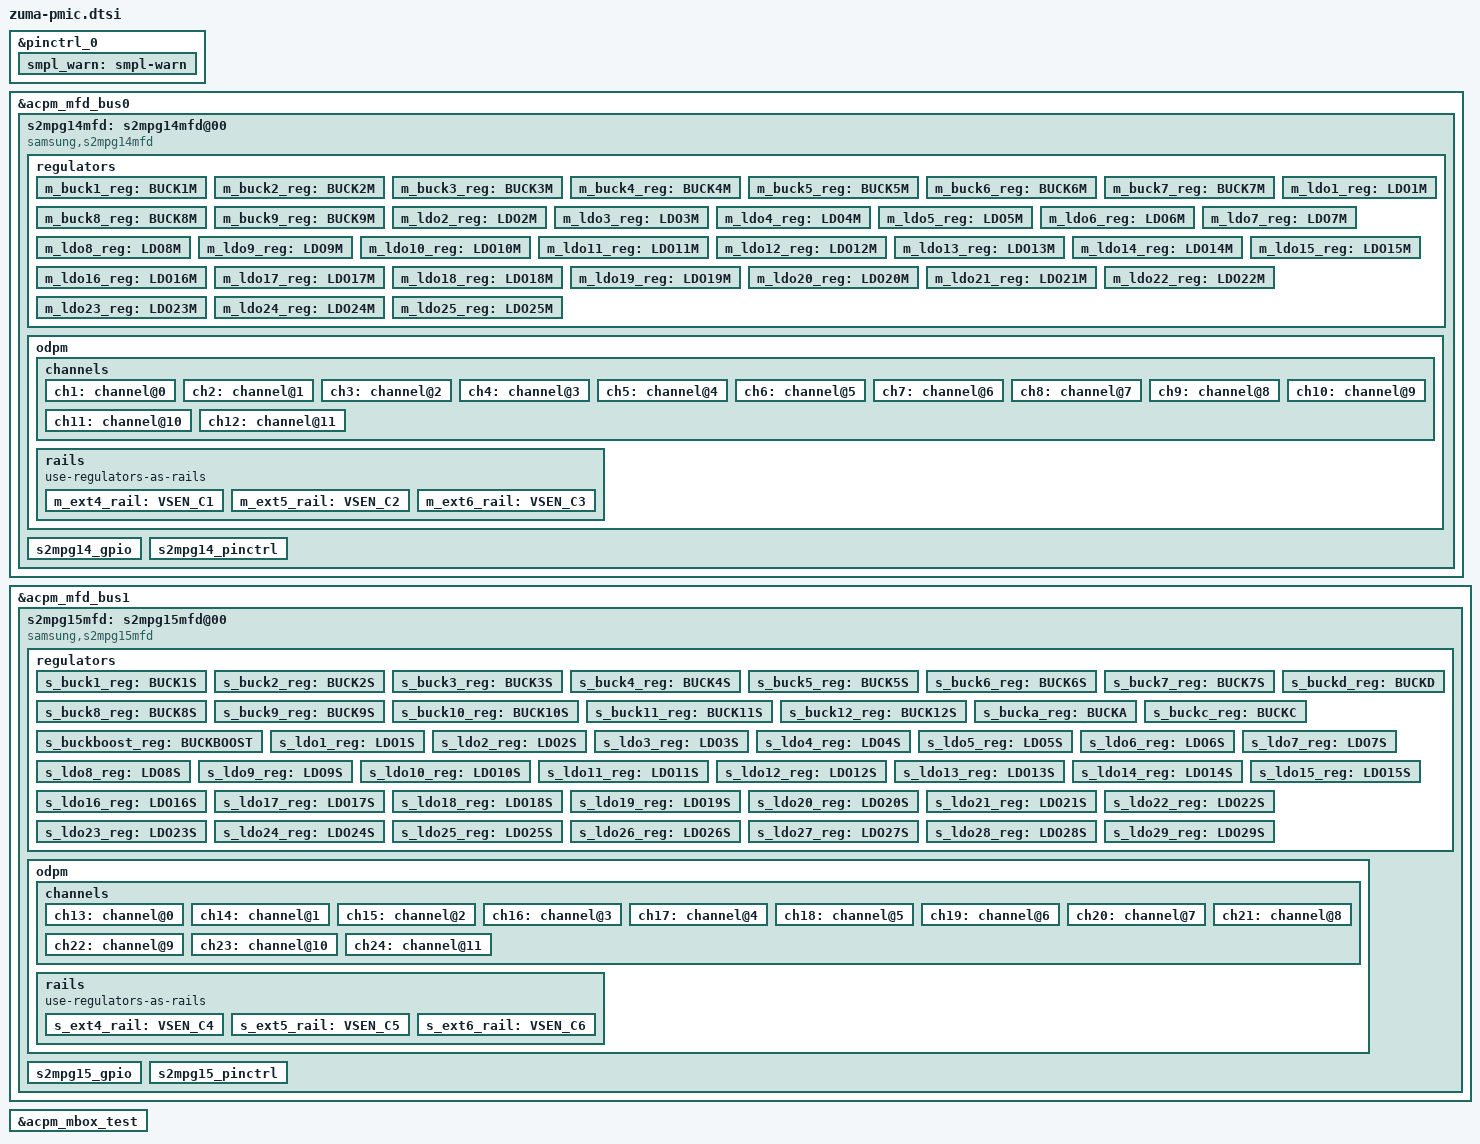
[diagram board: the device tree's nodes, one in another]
// SPDX-License-Identifier: GPL-2.0-only
/*
 * zuma pmic device tree source
 *
 * Copyright 2022 Google LLC.
 *
 */

#include <dt-bindings/gpio/gpio.h>
#include <dt-bindings/power/google-power.h>
#include <dt-bindings/power/s2mpg1x-power.h>
#include <dt-bindings/regulator/samsung,s2mpg-regulator.h>
#include <dt-bindings/interrupt-controller/zuma.h>

&pinctrl_0 {
	smpl_warn: smpl-warn {
		samsung,pins = "gpa9-4";
		samsung,pin-function = <EXYNOS_PIN_FUNC_EINT>;
		samsung,pin-pud = <EXYNOS_PIN_PULL_NONE>;
		samsung,pin-drv = <ZUMA_PIN_DRV_X1>;
	};
};

&acpm_mfd_bus0 {
	#address-cells = <1>;
	#size-cells = <0>;
	status = "okay";
	s2mpg14mfd: s2mpg14mfd@00 {
		compatible = "samsung,s2mpg14mfd";
		dev-name = "s2mpg14mfd";
		acpm-ipc-channel = <2>;
		acpm-speedy-channel = <0>;
		s2mpg14,wakeup = "enabled";
		reg = <0x1f>;
		interrupts = <GIC_SPI IRQ_INTCOMB_VGPIO2AP_ALIVE IRQ_TYPE_LEVEL_HIGH>;
		interrupt-parent = <&gic>;
		pinctrl-names = "default";
		pinctrl-0 = <&smpl_warn>;
		gpios = <&gpa9 4 GPIO_ACTIVE_LOW>,		/* SMPL_WARN_R_L */
			<&gpa10 0 GPIO_ACTIVE_HIGH>,		/* OCP_WARN_CPUCL1_R */
			<&gpa10 1 GPIO_ACTIVE_HIGH>,		/* OCP_WARN_CPUCL2_R */
			<&gpa10 2 GPIO_ACTIVE_HIGH>,		/* SOFT_OCP_WARN_CPUCL1_R */
			<&gpa10 3 GPIO_ACTIVE_HIGH>,		/* SOFT_OCP_WARN_CPUCL2_R */
			<&gpa9 2 GPIO_ACTIVE_HIGH>,		/* OCP_WARN_TPU_R */
			<&gpa9 3 GPIO_ACTIVE_HIGH>;		/* SOFT_OCP_WARN_TPU_R */
		#thermal-sensor-cells = <1>;

		/* SMPL_WARN */
		smpl_warn_en = <1>; /* 1 : enable , 0 : disable */
		smpl_warn_vth = <SMPL_2_9V>;
		/* SMPL_Hys[4:3] 00(Reserved), 01(200mV) */
		/*		 10(300mV), 11(Reserved) */
		smpl_warn_hys = <SMPL_HYST_200MV>;

		b2_ocp_warn_en = <OCP_WARN_ENABLE>;
		b2_ocp_warn_cnt = <OCP_WARN_2_CLOCK>;
		b2_ocp_warn_dvs_mask = <OCP_WARN_NOT_MASKED>;
		b2_ocp_warn_lvl = <OCP_WARN_LVL_2PH_8_A>;
		b2_ocp_warn_debounce_clk = <3>;

		b3_ocp_warn_en = <OCP_WARN_ENABLE>;
		b3_ocp_warn_cnt = <OCP_WARN_2_CLOCK>;
		b3_ocp_warn_dvs_mask = <OCP_WARN_NOT_MASKED>;
		b3_ocp_warn_lvl = <OCP_WARN_LVL_3PH_13_50_A>;
		b3_ocp_warn_debounce_clk = <3>;

		b7_ocp_warn_en = <OCP_WARN_ENABLE>;
		b7_ocp_warn_cnt = <OCP_WARN_2_CLOCK>;
		b7_ocp_warn_dvs_mask = <OCP_WARN_NOT_MASKED>;
		b7_ocp_warn_lvl = <OCP_WARN_LVL_3PH_13_50_A>;
		b7_ocp_warn_debounce_clk = <3>;

		b2_soft_ocp_warn_en = <OCP_WARN_ENABLE>;
		b2_soft_ocp_warn_cnt = <OCP_WARN_2_CLOCK>;
		b2_soft_ocp_warn_dvs_mask = <OCP_WARN_NOT_MASKED>;
		b2_soft_ocp_warn_lvl = <OCP_WARN_LVL_2PH_8_A>;
		b2_soft_ocp_warn_debounce_clk = <3>;

		b3_soft_ocp_warn_en = <OCP_WARN_ENABLE>;
		b3_soft_ocp_warn_cnt = <OCP_WARN_2_CLOCK>;
		b3_soft_ocp_warn_dvs_mask = <OCP_WARN_NOT_MASKED>;
		b3_soft_ocp_warn_lvl = <OCP_WARN_LVL_3PH_13_50_A>;
		b3_soft_ocp_warn_debounce_clk = <3>;

		b7_soft_ocp_warn_en = <OCP_WARN_ENABLE>;
		b7_soft_ocp_warn_cnt = <OCP_WARN_2_CLOCK>;
		b7_soft_ocp_warn_dvs_mask = <OCP_WARN_NOT_MASKED>;
		b7_soft_ocp_warn_lvl = <OCP_WARN_LVL_3PH_13_50_A>;
		b7_soft_ocp_warn_debounce_clk = <3>;

		/* BUCK OCP Detection */
		buck_ocp_ctrl1 = <0xBB>;
		buck_ocp_ctrl2 = <0xBB>;
		buck_ocp_ctrl3 = <0xBB>;
		buck_ocp_ctrl4 = <0xBB>;
		buck_ocp_ctrl5 = <0xBB>;

		/* RTC: wtsr/smpl */
		wtsr_en = <1>;
		coldrst_en = "disabled";
		smpl_en = "enabled";
		wtsr_timer_val = <RTC_WTSRT_2_000_SEC>;
		coldrst_timer_val = <RTC_WTSR_COLDTIMER_256_MSEC>;
		smpl_timer_val = <RTC_SMPLT_1_93_SEC>;
		sub_smpl_en = "disabled";
		check_jigon = <0>;

		/* RTC: If first boot, reset rtc to 1/1/2022 12:00:00(Sat) */
		init_time,sec = <0>;
		init_time,min = <0>;
		init_time,hour = <12>;
		init_time,mday = <1>;
		init_time,mon = <0>;
		init_time,year = <122>;
		init_time,wday = <6>;

		/* PCTRLSEL(VGPIO) 1~11 (CONTROL_SEL#) */
		sel_vgpio = <0xD3 0x1C 0xE3 0x01 0x63 0xC6
			0xE1 0x47 0x4D 0x96 0x09>;

		regulators {
			m_buck1_reg: BUCK1M {
				regulator-name = "S2MPG14_BUCK1";
				regulator-min-microvolt = <450000>;
				regulator-max-microvolt = <1300000>;
				regulator-always-on;
				regulator-initial-mode = <SEC_OPMODE_ON>;
				channel-mux-selection = <0x01>;
				schematic-name = "S1M_VDD_MIF";
				subsys-name = "MIF";
				buck_rail;
				channel-en-byte-offset = <0>;
				channel-en-index = <0x01>;
			};

			m_buck2_reg: BUCK2M {
				regulator-name = "S2MPG14_BUCK2";
				regulator-min-microvolt = <450000>;
				regulator-max-microvolt = <1300000>;
				regulator-always-on;
				regulator-initial-mode = <SEC_OPMODE_SUSPEND>;
				channel-mux-selection = <0x02>;
				schematic-name = "S2M_VDD_CPUCL2";
				subsys-name = "CPU(BIG)";
				buck_rail;
				channel-en-byte-offset = <0>;
				channel-en-index = <0x02>;
				odpm_disable_in_sleep;
			};

			m_buck3_reg: BUCK3M {
				regulator-name = "S2MPG14_BUCK3";
				regulator-min-microvolt = <450000>;
				regulator-max-microvolt = <1300000>;
				regulator-always-on;
				regulator-initial-mode = <SEC_OPMODE_SUSPEND>;
				channel-mux-selection = <0x03>;
				schematic-name = "S3M_VDD_CPUCL1";
				subsys-name = "CPU(MID)";
				buck_rail;
				channel-en-byte-offset = <0>;
				channel-en-index = <0x04>;
				odpm_disable_in_sleep;
			};

			m_buck4_reg: BUCK4M {
				regulator-name = "S2MPG14_BUCK4";
				regulator-min-microvolt = <450000>;
				regulator-max-microvolt = <1300000>;
				regulator-always-on;
				regulator-initial-mode = <SEC_OPMODE_SUSPEND>;
				channel-mux-selection = <0x04>;
				schematic-name = "S4M_VDD_CPUCL0";
				subsys-name = "CPU(LITTLE)";
				buck_rail;
				channel-en-byte-offset = <0>;
				channel-en-index = <0x08>;
				odpm_disable_in_sleep;
			};

			m_buck5_reg: BUCK5M {
				regulator-name = "S2MPG14_BUCK5";
				regulator-min-microvolt = <450000>;
				regulator-max-microvolt = <1300000>;
				regulator-always-on;
				regulator-initial-mode = <SEC_OPMODE_ON>;
				channel-mux-selection = <0x05>;
				schematic-name = "S5M_VDD_INT";
				subsys-name = "INT";
				buck_rail;
				channel-en-byte-offset = <0>;
				channel-en-index = <0x10>;
			};

			m_buck6_reg: BUCK6M {
				regulator-name = "S2MPG14_BUCK6";
				regulator-min-microvolt = <450000>;
				regulator-max-microvolt = <1500000>;
				regulator-always-on;
				regulator-initial-mode = <SEC_OPMODE_ON>;
				channel-mux-selection = <0x06>;
				schematic-name = "S6M_LLDO1";
				subsys-name = "LDO";
				buck_rail;
				channel-en-byte-offset = <0>;
				channel-en-index = <0x20>;
				odpm_disable_in_sleep;
			};

			m_buck7_reg: BUCK7M {
				regulator-name = "S2MPG14_BUCK7";
				regulator-min-microvolt = <450000>;
				regulator-max-microvolt = <1300000>;
				regulator-always-on;
				regulator-initial-mode = <SEC_OPMODE_SUSPEND>;
				channel-mux-selection = <0x07>;
				schematic-name = "S7M_VDD_TPU";
				subsys-name = "TPU";
				buck_rail;
				channel-en-byte-offset = <0>;
				channel-en-index = <0x40>;
				odpm_disable_in_sleep;
			};

			m_buck8_reg: BUCK8M {
				regulator-name = "S2MPG14_BUCK8";
				regulator-min-microvolt = <450000>;
				regulator-max-microvolt = <1300000>;
				regulator-always-on;
				regulator-initial-mode = <SEC_OPMODE_ON>;
				channel-mux-selection = <0x08>;
				schematic-name = "S8M_LLDO2";
				subsys-name = "LDO";
				buck_rail;
				channel-en-byte-offset = <0>;
				channel-en-index = <0x80>;
			};

			m_buck9_reg: BUCK9M {
				regulator-name = "S2MPG14_BUCK9";
				regulator-min-microvolt = <450000>;
				regulator-max-microvolt = <1300000>;
				regulator-always-on;
				regulator-initial-mode = <SEC_OPMODE_SUSPEND>;
				channel-mux-selection = <0x09>;
				schematic-name = "S9M_VDD_CPUCL0_M";
				subsys-name = "CPU(LITTLE)";
				buck_rail;
				channel-en-byte-offset = <1>;
				channel-en-index = <0x01>;
				odpm_disable_in_sleep;
			};

			m_ldo1_reg: LDO1M {
				regulator-name = "S2MPG14_LDO1";
				regulator-min-microvolt = <450000>;
				regulator-max-microvolt = <950000>;
				regulator-always-on;
				regulator-initial-mode = <SEC_OPMODE_ON>;
				channel-mux-selection = <0x21>;
				schematic-name = "L1M_ALIVE";
				subsys-name = "ALIVE";
			};

			m_ldo2_reg: LDO2M {
				regulator-name = "S2MPG14_LDO2";
				regulator-min-microvolt = <1600000>;
				regulator-max-microvolt = <1950000>;
				regulator-always-on;
				regulator-initial-mode = <SEC_OPMODE_ON>;
				channel-mux-selection = <0x22>;
				schematic-name = "L2M_ALIVE";
				subsys-name = "ALIVE";
			};

			m_ldo3_reg: LDO3M {
				regulator-name = "S2MPG14_LDO3";
				regulator-min-microvolt = <450000>;
				regulator-max-microvolt = <950000>;
				regulator-always-on;
				regulator-initial-mode = <SEC_OPMODE_ON>;
				channel-mux-selection = <0x23>;
				schematic-name = "L3M_VDD_AOC_RET";
				subsys-name = "AOC";
			};

			m_ldo4_reg: LDO4M {
				regulator-name = "S2MPG14_LDO4";
				regulator-min-microvolt = <2500000>;
				regulator-max-microvolt = <3300000>;
				regulator-always-on;
				regulator-initial-mode = <SEC_OPMODE_ON>;
				channel-mux-selection = <0x24>;
				schematic-name = "L4M_TS1_AVDD";
				subsys-name = "TS";
			};

			m_ldo5_reg: LDO5M {
				regulator-name = "S2MPG14_LDO5";
				regulator-min-microvolt = <1600000>;
				regulator-max-microvolt = <1950000>;
				regulator-always-on;
				regulator-initial-mode = <SEC_OPMODE_ON>;
				channel-mux-selection = <0x25>;
				schematic-name = "L5M_S5910_VDD18VD";
				subsys-name = "MODEM";
			};

			m_ldo6_reg: LDO6M {
				regulator-name = "S2MPG14_LDO6";
				regulator-min-microvolt = <725000>;
				regulator-max-microvolt = <1300000>;
				regulator-always-on;
				regulator-initial-mode = <SEC_OPMODE_ON>;
				channel-mux-selection = <0x26>;
				schematic-name = "L6M_HSI";
				subsys-name = "IO";
			};

			m_ldo7_reg: LDO7M {
				regulator-name = "S2MPG14_LDO7";
				regulator-min-microvolt = <1800000>;
				regulator-max-microvolt = <3350000>;
				regulator-initial-mode = <SEC_OPMODE_OFF>;
				channel-mux-selection = <0x27>;
				schematic-name = "L7M_DPAUX";
				subsys-name = "Display";
			};

			m_ldo8_reg: LDO8M {
				regulator-name = "S2MPG14_LDO8";
				regulator-min-microvolt = <450000>;
				regulator-max-microvolt = <950000>;
				regulator-initial-mode = <SEC_OPMODE_ON>;
				channel-mux-selection = <0x28>;
				schematic-name = "L8M_EUSB";
				subsys-name = "USB";
			};

			m_ldo9_reg: LDO9M {
				regulator-name = "S2MPG14_LDO9";
				regulator-min-microvolt = <725000>;
				regulator-max-microvolt = <1300000>;
				regulator-initial-mode = <SEC_OPMODE_ON>;
				channel-mux-selection = <0x29>;
				schematic-name = "L9M_EUSB";
				subsys-name = "USB";
			};

			m_ldo10_reg: LDO10M {
				regulator-name = "S2MPG14_LDO10";
				regulator-min-microvolt = <725000>;
				regulator-max-microvolt = <1300000>;
				regulator-always-on;
				regulator-initial-mode = <SEC_OPMODE_ON>;
				channel-mux-selection = <0x2A>;
				schematic-name = "L10M_AOC";
				subsys-name = "AOC";
			};

			m_ldo11_reg: LDO11M {
				regulator-name = "S2MPG14_LDO11";
				regulator-min-microvolt = <700000>;
				regulator-max-microvolt = <1300000>;
				regulator-always-on;
				regulator-initial-mode = <SEC_OPMODE_SUSPEND>;
				channel-mux-selection = <0x2B>;
				schematic-name = "L11M_VDD_CPUCL1_M";
				subsys-name = "CPU(MID)";
			};

			m_ldo12_reg: LDO12M {
				regulator-name = "S2MPG14_LDO12";
				regulator-min-microvolt = <700000>;
				regulator-max-microvolt = <1300000>;
				regulator-initial-mode = <SEC_OPMODE_OFF>;
				channel-mux-selection = <0x2C>;
				schematic-name = "L12M";
				subsys-name = "UNUSED";
			};

			m_ldo13_reg: LDO13M {
				regulator-name = "S2MPG14_LDO13";
				regulator-min-microvolt = <450000>;
				regulator-max-microvolt = <950000>;
				regulator-always-on;
				regulator-initial-mode = <SEC_OPMODE_SUSPEND>;
				channel-mux-selection = <0x2D>;
				schematic-name = "L13M_VDD_TPU_M";
				subsys-name = "TPU";
			};

			m_ldo14_reg: LDO14M {
				regulator-name = "S2MPG14_LDO14";
				regulator-min-microvolt = <2500000>;
				regulator-max-microvolt = <3300000>;
				regulator-always-on;
				regulator-initial-mode = <SEC_OPMODE_ON>;
				channel-mux-selection = <0x2E>;
				schematic-name = "L14M_DISP_VCI";
				subsys-name = "Display";
			};

			m_ldo15_reg: LDO15M {
				regulator-name = "S2MPG14_LDO15";
				regulator-min-microvolt = <450000>;
				regulator-max-microvolt = <950000>;
				regulator-initial-mode = <SEC_OPMODE_OFF>;
				channel-mux-selection = <0x2F>;
				schematic-name = "L15M";
				subsys-name = "UNUSED";
			};

			m_ldo16_reg: LDO16M {
				regulator-name = "S2MPG14_LDO16";
				regulator-min-microvolt = <725000>;
				regulator-max-microvolt = <1300000>;
				regulator-always-on;
				regulator-initial-mode = <SEC_OPMODE_ON>;
				channel-mux-selection = <0x30>;
				schematic-name = "L16M_PCIE0";
				subsys-name = "PCIE";
			};

			m_ldo17_reg: LDO17M {
				regulator-name = "S2MPG14_LDO17";
				regulator-min-microvolt = <700000>;
				regulator-max-microvolt = <1300000>;
				regulator-always-on;
				regulator-initial-mode = <SEC_OPMODE_SUSPEND>;
				channel-mux-selection = <0x31>;
				schematic-name = "L17M_VDD_CPUCL2_M";
				subsys-name = "CPU(BIG)";
			};

			m_ldo18_reg: LDO18M {
				regulator-name = "S2MPG14_LDO18";
				regulator-min-microvolt = <725000>;
				regulator-max-microvolt = <1300000>;
				regulator-always-on;
				regulator-initial-mode = <SEC_OPMODE_ON>;
				channel-mux-selection = <0x32>;
				schematic-name = "L18M_PCIE0";
				subsys-name = "PCIE";
			};

			m_ldo19_reg: LDO19M {
				regulator-name = "S2MPG14_LDO19";
				regulator-min-microvolt = <2500000>;
				regulator-max-microvolt = <3300000>;
				regulator-initial-mode = <SEC_OPMODE_ON>;
				channel-mux-selection = <0x33>;
				schematic-name = "L19M_EUSB";
				subsys-name = "USB";
			};

			m_ldo20_reg: LDO20M {
				regulator-name = "S2MPG14_LDO20";
				regulator-min-microvolt = <1600000>;
				regulator-max-microvolt = <1950000>;
				regulator-always-on;
				regulator-initial-mode = <SEC_OPMODE_ON>;
				channel-mux-selection = <0x34>;
				schematic-name = "L20M_DMIC1";
				subsys-name = "DMIC";
			};

			m_ldo21_reg: LDO21M {
				regulator-name = "S2MPG14_LDO21";
				regulator-min-microvolt = <2500000>;
				regulator-max-microvolt = <3300000>;
				regulator-always-on;
				regulator-initial-mode = <SEC_OPMODE_ON>;
				channel-mux-selection = <0x35>;
				schematic-name = "L21M_GSC";
				subsys-name = "GSC";
			};

			m_ldo22_reg: LDO22M {
				regulator-name = "S2MPG14_LDO22";
				regulator-min-microvolt = <725000>;
				regulator-max-microvolt = <1300000>;
				regulator-always-on;
				regulator-initial-mode = <SEC_OPMODE_ON>;
				channel-mux-selection = <0x36>;
				schematic-name = "L22M_DISP_VDDD";
				subsys-name = "Display";
			};

			m_ldo23_reg: LDO23M {
				regulator-name = "S2MPG14_LDO23";
				regulator-min-microvolt = <1600000>;
				regulator-max-microvolt = <1950000>;
				regulator-initial-mode = <SEC_OPMODE_OFF>;
				channel-mux-selection = <0x37>;
				schematic-name = "L23M";
				subsys-name = "UNUSED";
			};

			m_ldo24_reg: LDO24M {
				regulator-name = "S2MPG14_LDO24";
				regulator-min-microvolt = <1600000>;
				regulator-max-microvolt = <1950000>;
				regulator-initial-mode = <SEC_OPMODE_OFF>;
				channel-mux-selection = <0x38>;
				schematic-name = "L24M";
				subsys-name = "UNUSED";
			};

			m_ldo25_reg: LDO25M {
				regulator-name = "S2MPG14_LDO25";
				regulator-min-microvolt = <1600000>;
				regulator-max-microvolt = <1950000>;
				regulator-always-on;
				regulator-initial-mode = <SEC_OPMODE_ON>;
				channel-mux-selection = <0x39>;
				schematic-name = "L25M_TS1_DVDD";
				subsys-name = "TS";
			};
		};

		odpm {
			chip-name = "S2MPG14";
			sample-rate-uhz = <125000000>;
			sample-rate-external-uhz = <31250000>;

			/* 120 minutes was selected as the spec
			 * for the sample rate (125sps)
			 *
			 * Note, this can be verified based on the
			 * number of bits in the ACC registers.
			 * ACC_COUNT is 20 bits. Thus,
			 * 2^20 - 1 = 1048575 ==> 8388.6 seconds
			 * ==> 139.81 minutes
			 */
			max-refresh-time-ms = <(120 * 60 * 1000)>;
			channels {
				ch1: channel@0 {
					rail-name = "BUCK1M";
					channel_enabled;
				};
				ch2: channel@1 {
					rail-name = "BUCK2M";
					channel_enabled;
				};
				ch3: channel@2 {
					rail-name = "BUCK3M";
					channel_enabled;
				};
				ch4: channel@3 {
					rail-name = "BUCK4M";
					channel_enabled;
				};
				ch5: channel@4 {
					rail-name = "BUCK5M";
					channel_enabled;
				};
				ch6: channel@5 {
					rail-name = "BUCK6M";
					channel_enabled;
				};
				ch7: channel@6 {
					rail-name = "BUCK7M";
					channel_enabled;
				};
				ch8: channel@7 {
					rail-name = "BUCK8M";
					channel_enabled;
				};
				ch9: channel@8 {
					rail-name = "LDO15M";
					channel_enabled;
				};
				ch10: channel@9 {
					rail-name = "BUCK9M";
					channel_enabled;
				};
				ch11: channel@10 {
					rail-name = "VSEN_C2";
					channel_enabled;
				};
				ch12: channel@11 {
					rail-name = "VSEN_C3";
					channel_enabled;
				};
			};
			rails {
				use-regulators-as-rails;
				/* Additional rails */
				/* Note; VSEN_P is not supported */
				m_ext4_rail: VSEN_C1 {
					external_rail;
					channel-en-index = <1>;
					channel-mux-selection = <0x5C>;
					shunt-res-uohms = <10000>;
					schematic-name = "VSYS_PWR_DISPLAY";
					subsys-name = "Display";
				};
				m_ext5_rail: VSEN_C2 {
					external_rail;
					channel-en-index = <2>;
					channel-mux-selection = <0x5D>;
					shunt-res-uohms = <5000>;
					schematic-name = "VSYS_PWR_MODEM";
					subsys-name = "MODEM";
				};
				m_ext6_rail: VSEN_C3 {
					external_rail;
					channel-en-index = <4>;
					channel-mux-selection = <0x5E>;
					shunt-res-uohms = <5000>;
					schematic-name = "VSYS_PWR_RFFE";
					subsys-name = "Cellular";
				};
			};
		};

		s2mpg14_gpio: s2mpg14_gpio {
			gpio-controller;
			#gpio-cells = <2>;
			ngpios = <6>;
			gpio-ranges = <&s2mpg14_pinctrl 0 0 6>;
		};

		s2mpg14_pinctrl: s2mpg14_pinctrl {
		};
	};
};

&acpm_mfd_bus1 {
	#address-cells = <1>;
	#size-cells = <0>;
	status = "okay";
	s2mpg15mfd: s2mpg15mfd@00 {
		compatible = "samsung,s2mpg15mfd";
		dev-name = "s2mpg15mfd";
		acpm-ipc-channel = <2>;
		acpm-speedy-channel = <1>;
		s2mpg15,wakeup = "enabled";
		reg = <0x2f>;
		interrupts = <1 0 0>, // OCP_WARN_GPU
			     <1 0 1>; // SOFT_OCP_WARN_GPU
		interrupt-parent = <&gpa0>;
		pinctrl-names = "default";

		gpios = <&gpp17 0 GPIO_ACTIVE_HIGH>,
			<&gpp17 1 GPIO_ACTIVE_HIGH>;
		#thermal-sensor-cells = <1>;

		b2_ocp_warn_en = <OCP_WARN_ENABLE>;
		b2_ocp_warn_cnt = <OCP_WARN_2_CLOCK>;
		b2_ocp_warn_dvs_mask = <OCP_WARN_NOT_MASKED>;
		b2_ocp_warn_lvl = <OCP_WARN_LVL_2PH_8_A>;
		b2_ocp_warn_debounce_clk = <3>;

		b2_soft_ocp_warn_en = <OCP_WARN_ENABLE>;
		b2_soft_ocp_warn_cnt = <OCP_WARN_2_CLOCK>;
		b2_soft_ocp_warn_dvs_mask = <OCP_WARN_NOT_MASKED>;
		b2_soft_ocp_warn_lvl = <OCP_WARN_LVL_2PH_8_A>;
		b2_soft_ocp_warn_debounce_clk = <3>;

		/* BUCK OCP Detection */
		buck_ocp_ctrl1 = <0xBB>;
		buck_ocp_ctrl2 = <0xBA>;
		buck_ocp_ctrl3 = <0xBB>;
		buck_ocp_ctrl4 = <0xBB>;
		buck_ocp_ctrl5 = <0xBB>;
		buck_ocp_ctrl6 = <0xBB>;
		buck_ocp_ctrl7 = <0xBB>;
		buck_ocp_ctrl8 = <0xBB>;

		/* wtsr */
		wtsr_en = <1>;

		/* PCTRLSEL(VGPIO) 1~10 (CONTROL_SEL#) */
		sel_vgpio = <0xA3 0xF3 0x3A 0x33 0x0B 0xAB
			0x33 0x9C 0x39 0x03>;

		regulators {
			s_buck1_reg: BUCK1S {
				regulator-name = "S2MPG15_BUCK1";
				regulator-min-microvolt = <450000>;
				regulator-max-microvolt = <1300000>;
				regulator-always-on;
				regulator-initial-mode = <SEC_OPMODE_ON>;
				channel-mux-selection = <0x01>;
				schematic-name = "S1S_VDD_CAM";
				subsys-name = "Multimedia";
				buck_rail;
				channel-en-byte-offset = <0>;
				channel-en-index = <0x01>;
				odpm_disable_in_sleep;
			};

			s_buck2_reg: BUCK2S {
				regulator-name = "S2MPG15_BUCK2";
				regulator-min-microvolt = <450000>;
				regulator-max-microvolt = <1300000>;
				regulator-always-on;
				regulator-initial-mode = <SEC_OPMODE_SUSPEND>;
				channel-mux-selection = <0x02>;
				schematic-name = "S2S_VDD_G3D";
				subsys-name = "GPU";
				buck_rail;
				channel-en-byte-offset = <0>;
				channel-en-index = <0x02>;
				odpm_disable_in_sleep;
			};

			s_buck3_reg: BUCK3S {
				regulator-name = "S2MPG15_BUCK3";
				regulator-min-microvolt = <450000>;
				regulator-max-microvolt = <1300000>;
				regulator-always-on;
				regulator-initial-mode = <SEC_OPMODE_ON>;
				channel-mux-selection = <0x03>;
				schematic-name = "S3S_LLDO1";
				subsys-name = "LDO";
				buck_rail;
				channel-en-byte-offset = <0>;
				channel-en-index = <0x04>;
			};

			s_buck4_reg: BUCK4S {
				regulator-name = "S2MPG15_BUCK4";
				regulator-min-microvolt = <450000>;
				regulator-max-microvolt = <1300000>;
				regulator-always-on;
				regulator-initial-mode = <SEC_OPMODE_ON>;
				channel-mux-selection = <0x04>;
				schematic-name = "S4S_VDD2H_MEM";
				subsys-name = "DDR";
				buck_rail;
				channel-en-byte-offset = <0>;
				channel-en-index = <0x08>;
			};

			s_buck5_reg: BUCK5S {
				regulator-name = "S2MPG15_BUCK5";
				regulator-min-microvolt = <300000>;
				regulator-max-microvolt = <1300000>;
				regulator-always-on;
				regulator-initial-mode = <SEC_OPMODE_ON>;
				channel-mux-selection = <0x05>;
				schematic-name = "S5S_VDDQ_MEM";
				subsys-name = "DDR";
				buck_rail;
				channel-en-byte-offset = <0>;
				channel-en-index = <0x10>;
			};

			s_buck6_reg: BUCK6S {
				regulator-name = "S2MPG15_BUCK6";
				regulator-min-microvolt = <1000000>;
				regulator-max-microvolt = <1500000>;
				regulator-always-on;
				regulator-initial-mode = <SEC_OPMODE_ON>;
				channel-mux-selection = <0x06>;
				schematic-name = "S6S_LLDO2";
				subsys-name = "LDO";
				buck_rail;
				channel-en-byte-offset = <0>;
				channel-en-index = <0x20>;
			};

			s_buck7_reg: BUCK7S {
				regulator-name = "S2MPG15_BUCK7";
				regulator-min-microvolt = <1500000>;
				regulator-max-microvolt = <2200000>;
				regulator-always-on;
				regulator-initial-mode = <SEC_OPMODE_ON>;
				channel-mux-selection = <0x07>;
				schematic-name = "S7S_MLDO";
				subsys-name = "LDO";
				buck_rail;
				channel-en-byte-offset = <0>;
				channel-en-index = <0x40>;
			};

			s_buck8_reg: BUCK8S {
				regulator-name = "S2MPG15_BUCK8";
				regulator-min-microvolt = <450000>;
				regulator-max-microvolt = <1300000>;
				regulator-always-on;
				regulator-initial-mode = <SEC_OPMODE_SUSPEND>;
				channel-mux-selection = <0x08>;
				schematic-name = "S8S_VDD_G3D_L2";
				subsys-name = "GPU";
				buck_rail;
				channel-en-byte-offset = <0>;
				channel-en-index = <0x80>;
				odpm_disable_in_sleep;
			};

			s_buck9_reg: BUCK9S {
				regulator-name = "S2MPG15_BUCK9";
				regulator-min-microvolt = <450000>;
				regulator-max-microvolt = <1300000>;
				regulator-always-on;
				regulator-initial-mode = <SEC_OPMODE_ON>;
				channel-mux-selection = <0x09>;
				schematic-name = "S9S_VDD_AOC";
				subsys-name = "AOC";
				buck_rail;
				channel-en-byte-offset = <1>;
				channel-en-index = <0x01>;
			};

			s_buck10_reg: BUCK10S {
				regulator-name = "S2MPG15_BUCK10";
				regulator-min-microvolt = <450000>;
				regulator-max-microvolt = <1300000>;
				regulator-always-on;
				regulator-initial-mode = <SEC_OPMODE_ON>;
				channel-mux-selection = <0x0A>;
				schematic-name = "S10S_VDD_SLC_M";
				subsys-name = "SLC";
				buck_rail;
				channel-en-byte-offset = <1>;
				channel-en-index = <0x02>;
			};

			s_buck11_reg: BUCK11S {
				regulator-name = "S2MPG15_BUCK11";
				regulator-min-microvolt = <450000>;
				regulator-max-microvolt = <1300000>;
				regulator-always-on;
				regulator-initial-mode = <SEC_OPMODE_ON>;
				channel-mux-selection = <0x0B>;
				schematic-name = "S11S_G3D_GLB";
				subsys-name = "GPU";
				buck_rail;
				channel-en-byte-offset = <1>;
				channel-en-index = <0x04>;
				odpm_disable_in_sleep;
			};

			s_buck12_reg: BUCK12S {
				regulator-name = "S2MPG15_BUCK12";
				regulator-min-microvolt = <450000>;
				regulator-max-microvolt = <1300000>;
				regulator-always-on;
				regulator-initial-mode = <SEC_OPMODE_ON>;
				channel-mux-selection = <0x0C>;
				schematic-name = "S12S_VDD_AUR";
				subsys-name = "AUR";
				buck_rail;
				channel-en-byte-offset = <1>;
				channel-en-index = <0x08>;
			};

			s_buckd_reg: BUCKD {
				regulator-name = "S2MPG15_BUCKD";
				regulator-min-microvolt = <2400000>;
				regulator-max-microvolt = <3300000>;
				regulator-always-on;
				regulator-initial-mode = <SEC_OPMODE_SUSPEND>;
				channel-mux-selection = <0x0D>;
				schematic-name = "SD";
				subsys-name = "IO";
				buck_rail;
				channel-en-byte-offset = <1>;
				channel-en-index = <0x10>;
			};

			s_bucka_reg: BUCKA {
				regulator-name = "S2MPG15_BUCKA";
				regulator-min-microvolt = <1700000>;
				regulator-max-microvolt = <2100000>;
				regulator-always-on;
				regulator-initial-mode = <SEC_OPMODE_ON>;
				channel-mux-selection = <0x0E>;
				schematic-name = "SA";
				subsys-name = "IO";
				buck_rail;
				channel-en-byte-offset = <1>;
				channel-en-index = <0x20>;
			};

			s_buckc_reg: BUCKC {
				regulator-name = "S2MPG15_BUCKC";
				regulator-min-microvolt = <450000>;
				regulator-max-microvolt = <1350000>;
				regulator-always-on;
				regulator-initial-mode = <SEC_OPMODE_SUSPEND>;
				channel-mux-selection = <0x0F>;
				schematic-name = "SC";
				subsys-name = "IO";
				buck_rail;
				channel-en-byte-offset = <1>;
				channel-en-index = <0x40>;
			};

			s_buckboost_reg: BUCKBOOST {
				regulator-name = "S2MPG15_BUCKBOOST";
				regulator-min-microvolt = <3000000>;
				regulator-max-microvolt = <3600000>;
				regulator-always-on;
				regulator-initial-mode = <SEC_OPMODE_ON>;
				channel-mux-selection = <0x10>;
				schematic-name = "BB_HLDO";
				subsys-name = "LDO";
				buck_rail;
				channel-en-byte-offset = <1>;
				channel-en-index = <0x80>;
			};

			s_ldo1_reg: LDO1S {
				regulator-name = "S2MPG15_LDO1";
				regulator-min-microvolt = <700000>;
				regulator-max-microvolt = <1300000>;
				regulator-always-on;
				regulator-initial-mode = <SEC_OPMODE_SUSPEND>;
				channel-mux-selection = <0x21>;
				schematic-name = "L1S_VDD_G3D_M";
				subsys-name = "GPU";
			};

			s_ldo2_reg: LDO2S {
				regulator-name = "S2MPG15_LDO2";
				regulator-min-microvolt = <700000>;
				regulator-max-microvolt = <1300000>;
				regulator-always-on;
				regulator-initial-mode = <SEC_OPMODE_ON>;
				channel-mux-selection = <0x22>;
				schematic-name = "L2S_PLL_MIPI_UFS";
				subsys-name = "PLL";
			};

			s_ldo3_reg: LDO3S {
				regulator-name = "S2MPG15_LDO3";
				regulator-min-microvolt = <725000>;
				regulator-max-microvolt = <1300000>;
				regulator-always-on;
				regulator-initial-mode = <SEC_OPMODE_ON>;
				channel-mux-selection = <0x23>;
				schematic-name = "L3S_PCIE1";
				subsys-name = "PCIE";
			};

			s_ldo4_reg: LDO4S {
				regulator-name = "S2MPG15_LDO4";
				regulator-min-microvolt = <1600000>;
				regulator-max-microvolt = <1950000>;
				channel-mux-selection = <0x24>;
				schematic-name = "L4S";
				subsys-name = "UNUSED";
			};

			s_ldo5_reg: LDO5S {
				regulator-name = "S2MPG15_LDO5";
				regulator-min-microvolt = <2500000>;
				regulator-max-microvolt = <3300000>;
				regulator-boot-on;
				regulator-initial-mode = <SEC_OPMODE_ON>;
				channel-mux-selection = <0x25>;
				schematic-name = "L5S_PROX";
				subsys-name = "Prox";
			};

			s_ldo6_reg: LDO6S {
				regulator-name = "S2MPG15_LDO6";
				regulator-min-microvolt = <2500000>;
				regulator-max-microvolt = <3300000>;
				regulator-initial-mode = <SEC_OPMODE_OFF>;
				channel-mux-selection = <0x26>;
				schematic-name = "L6S";
				subsys-name = "UNUSED";
			};

			s_ldo7_reg: LDO7S {
				regulator-name = "S2MPG15_LDO7";
				regulator-min-microvolt = <1600000>;
				regulator-max-microvolt = <1950000>;
				regulator-boot-on;
				regulator-initial-mode = <SEC_OPMODE_ON>;
				channel-mux-selection = <0x27>;
				schematic-name = "L7S_SENSORS_FPS";
				subsys-name = "FPS";
			};

			s_ldo8_reg: LDO8S {
				regulator-name = "S2MPG15_LDO8";
				regulator-min-microvolt = <2500000>;
				regulator-max-microvolt = <3300000>;
				regulator-initial-mode = <SEC_OPMODE_OFF>;
				channel-mux-selection = <0x28>;
				schematic-name = "L8S";
				subsys-name = "UNUSED";
			};

			s_ldo9_reg: LDO9S {
				regulator-name = "S2MPG15_LDO9";
				regulator-min-microvolt = <725000>;
				regulator-max-microvolt = <1300000>;
				regulator-always-on;
				regulator-initial-mode = <SEC_OPMODE_ON>;
				channel-mux-selection = <0x29>;
				schematic-name = "L9S_GNSS_CORE";
				subsys-name = "GPS";
			};

			s_ldo10_reg: LDO10S {
				regulator-name = "S2MPG15_LDO10";
				regulator-min-microvolt = <1600000>;
				regulator-max-microvolt = <1950000>;
				regulator-always-on;
				regulator-initial-mode = <SEC_OPMODE_ON>;
				channel-mux-selection = <0x2A>;
				schematic-name = "L10S_GNSS_RF";
				subsys-name = "GPS";
			};

			s_ldo11_reg: LDO11S {
				regulator-name = "S2MPG15_LDO11";
				regulator-min-microvolt = <1600000>;
				regulator-max-microvolt = <1950000>;
				regulator-always-on;
				regulator-initial-mode = <SEC_OPMODE_ON>;
				channel-mux-selection = <0x2B>;
				schematic-name = "L11S_GNSS_AUX";
				subsys-name = "GPS";
			};

			s_ldo12_reg: LDO12S {
				regulator-name = "S2MPG15_LDO12";
				regulator-min-microvolt = <1600000>;
				regulator-max-microvolt = <1950000>;
				regulator-initial-mode = <SEC_OPMODE_OFF>;
				channel-mux-selection = <0x2C>;
				schematic-name = "L12S_TS2_DVDD";
				subsys-name = "TS";
			};

			s_ldo13_reg: LDO13S {
				regulator-name = "S2MPG15_LDO13";
				regulator-min-microvolt = <1600000>;
				regulator-max-microvolt = <1950000>;
				regulator-initial-mode = <SEC_OPMODE_OFF>;
				channel-mux-selection = <0x2D>;
				schematic-name = "L13S";
				subsys-name = "UNUSED";
			};

			s_ldo14_reg: LDO14S {
				regulator-name = "S2MPG15_LDO14";
				regulator-min-microvolt = <1600000>;
				regulator-max-microvolt = <1950000>;
				regulator-initial-mode = <SEC_OPMODE_OFF>;
				channel-mux-selection = <0x2E>;
				schematic-name = "L14S";
				subsys-name = "UNUSED";
			};

			s_ldo15_reg: LDO15S {
				regulator-name = "S2MPG15_LDO15";
				regulator-min-microvolt = <2500000>;
				regulator-max-microvolt = <3300000>;
				regulator-always-on;
				regulator-initial-mode = <SEC_OPMODE_ON>;
				channel-mux-selection = <0x2F>;
				schematic-name = "L15S_UDFPS";
				subsys-name = "FPS";
			};

			s_ldo16_reg: LDO16S {
				regulator-name = "S2MPG15_LDO16";
				regulator-min-microvolt = <2500000>;
				regulator-max-microvolt = <3300000>;
				regulator-initial-mode = <SEC_OPMODE_OFF>;
				channel-mux-selection = <0x30>;
				schematic-name = "L16S";
				subsys-name = "UNUSED";
			};

			s_ldo17_reg: LDO17S {
				regulator-name = "S2MPG15_LDO17";
				regulator-min-microvolt = <1600000>;
				regulator-max-microvolt = <19500000>;
				regulator-initial-mode = <SEC_OPMODE_OFF>;
				channel-mux-selection = <0x31>;
				schematic-name = "L17S";
				subsys-name = "UNUSED";
			};

			s_ldo18_reg: LDO18S {
				regulator-name = "S2MPG15_LDO18";
				regulator-min-microvolt = <2500000>;
				regulator-max-microvolt = <3300000>;
				regulator-initial-mode = <SEC_OPMODE_OFF>;
				channel-mux-selection = <0x32>;
				schematic-name = "L18S";
				subsys-name = "UNUSED";
			};

			s_ldo19_reg: LDO19S {
				regulator-name = "S2MPG15_LDO19";
				regulator-min-microvolt = <1600000>;
				regulator-max-microvolt = <1950000>;
				regulator-always-on;
				regulator-initial-mode = <SEC_OPMODE_ON>;
				channel-mux-selection = <0x33>;
				schematic-name = "L19S_DMIC3";
				subsys-name = "DMIC";
			};

			s_ldo20_reg: LDO20S {
				regulator-name = "S2MPG15_LDO20";
				regulator-min-microvolt = <1600000>;
				regulator-max-microvolt = <1950000>;
				regulator-always-on;
				regulator-initial-mode = <SEC_OPMODE_ON>;
				channel-mux-selection = <0x34>;
				schematic-name = "L20S_DMIC45";
				subsys-name = "DMIC";
			};

			s_ldo21_reg: LDO21S {
				regulator-name = "S2MPG15_LDO21";
				regulator-min-microvolt = <725000>;
				regulator-max-microvolt = <1300000>;
				regulator-always-on;
				regulator-initial-mode = <SEC_OPMODE_ON>;
				channel-mux-selection = <0x35>;
				schematic-name = "L21S_VDD2L_MEM";
				subsys-name = "DDR";
			};

			s_ldo22_reg: LDO22S {
				regulator-name = "S2MPG15_LDO22";
				regulator-min-microvolt = <1600000>;
				regulator-max-microvolt = <1950000>;
				regulator-initial-mode = <SEC_OPMODE_OFF>;
				channel-mux-selection = <0x36>;
				schematic-name = "L22S";
				subsys-name = "UNUSED";
			};

			s_ldo23_reg: LDO23S {
				regulator-name = "S2MPG15_LDO23";
				regulator-min-microvolt = <700000>;
				regulator-max-microvolt = <1300000>;
				regulator-initial-mode = <SEC_OPMODE_OFF>;
				channel-mux-selection = <0x37>;
				schematic-name = "L23S";
				subsys-name = "UNUSED";
			};

			s_ldo24_reg: LDO24S {
				regulator-name = "S2MPG15_LDO24";
				regulator-min-microvolt = <725000>;
				regulator-max-microvolt = <1300000>;
				regulator-always-on;
				regulator-initial-mode = <SEC_OPMODE_ON>;
				channel-mux-selection = <0x38>;
				schematic-name = "L24S_HSI";
				subsys-name = "IO";
			};

			s_ldo25_reg: LDO25S {
				regulator-name = "S2MPG15_LDO25";
				regulator-min-microvolt = <2500000>;
				regulator-max-microvolt = <3300000>;
				regulator-initial-mode = <SEC_OPMODE_OFF>;
				channel-mux-selection = <0x39>;
				schematic-name = "L25S";
				subsys-name = "UNUSED";
			};

			s_ldo26_reg: LDO26S {
				regulator-name = "S2MPG15_LDO26";
				regulator-min-microvolt = <2500000>;
				regulator-max-microvolt = <3300000>;
				regulator-initial-mode = <SEC_OPMODE_OFF>;
				channel-mux-selection = <0x3A>;
				schematic-name = "L26S_TS2_AVDD";
				subsys-name = "TS";
			};

			s_ldo27_reg: LDO27S {
				regulator-name = "S2MPG15_LDO27";
				regulator-min-microvolt = <1600000>;
				regulator-max-microvolt = <1950000>;
				regulator-initial-mode = <SEC_OPMODE_OFF>;
				channel-mux-selection = <0x3B>;
				schematic-name = "L27S";
				subsys-name = "UNUSED";
			};

			s_ldo28_reg: LDO28S {
				regulator-name = "S2MPG15_LDO28";
				regulator-min-microvolt = <2500000>;
				regulator-max-microvolt = <3300000>;
				regulator-initial-mode = <SEC_OPMODE_OFF>;
				channel-mux-selection = <0x3C>;
				schematic-name = "L28S";
				subsys-name = "UNUSED";
			};

			s_ldo29_reg: LDO29S {
				regulator-name = "S2MPG15_LDO29";
				regulator-min-microvolt = <1600000>;
				regulator-max-microvolt = <1950000>;
				regulator-initial-mode = <SEC_OPMODE_OFF>;
				channel-mux-selection = <0x3D>;
				schematic-name = "L29S";
				subsys-name = "UNUSED";
			};
		};

		odpm {
			chip-name = "S2MPG15";
			sample-rate-uhz = <125000000>;
			sample-rate-external-uhz = <31250000>;

			/* 120 minutes was selected as the spec
			 * for the sample rate (125sps)
			 *
			 * Note, this can be verified based on the
			 * number of bits in the ACC registers.
			 * ACC_COUNT is 20 bits. Thus,
			 * 2^20 - 1 = 1048575 ==> 8388.6 seconds
			 * ==> 139.81 minutes
			 */
			max-refresh-time-ms = <(120 * 60 * 1000)>;
			channels {
				ch13: channel@0 {
					rail-name = "BUCK1S";
					channel_enabled;
				};
				ch14: channel@1 {
					rail-name = "BUCK2S";
					channel_enabled;
				};
				ch15: channel@2 {
					rail-name = "BUCK4S";
					channel_enabled;
				};
				ch16: channel@3 {
					rail-name = "BUCK5S";
					channel_enabled;
				};
				ch17: channel@4 {
					rail-name = "BUCK8S";
					channel_enabled;
				};
				ch18: channel@5 {
					rail-name = "BUCK9S";
					channel_enabled;
				};
				ch19: channel@6 {
					rail-name = "LDO2S";
					channel_enabled;
				};
				ch20: channel@7 {
					rail-name = "LDO9S";
					channel_enabled;
				};
				ch21: channel@8 {
					rail-name = "LDO29S";
					channel_enabled;
				};
				ch22: channel@9 {
					rail-name = "VSEN_C4";
					channel_enabled;
				};
				ch23: channel@10 {
					rail-name = "VSEN_C5";
					channel_enabled;
				};
				ch24: channel@11 {
					rail-name = "VSEN_C6";
					channel_enabled;
				};
			};
			rails {
				use-regulators-as-rails;
				/* Additional rails */
				/* Note; VSEN_P is not supported */
				s_ext4_rail: VSEN_C4 {
					external_rail;
					channel-en-index = <1>;
					channel-mux-selection = <0x5C>;
					shunt-res-uohms = <10000>;
					schematic-name = "VSYS_PWR_WLAN_BT";
					subsys-name = "WLAN-BT";
				};
				s_ext5_rail: VSEN_C5 {
					external_rail;
					channel-en-index = <2>;
					channel-mux-selection = <0x5D>;
					shunt-res-uohms = <5000>;
					schematic-name = "VSYS_PWR_IFPMIC";
					subsys-name = "IF_PMIC";
				};
				s_ext6_rail: VSEN_C6 {
					external_rail;
					channel-en-index = <4>;
					channel-mux-selection = <0x5E>;
					shunt-res-uohms = <5000>;
					schematic-name = "VSYS_PWR_MMWAVE";
					subsys-name = "Cellular";
				};
			};
		};

		s2mpg15_gpio: s2mpg15_gpio {
			gpio-controller;
			#gpio-cells = <2>;
			ngpios = <10>;
			gpio-ranges = <&s2mpg15_pinctrl 0 0 10>;
		};

		s2mpg15_pinctrl: s2mpg15_pinctrl {
		};
	};
};

&acpm_mbox_test {
	main-pmic = <&s2mpg14mfd>;
	sub-pmic = <&s2mpg15mfd>;
	acpm-ipc-channel = <2>;
};
